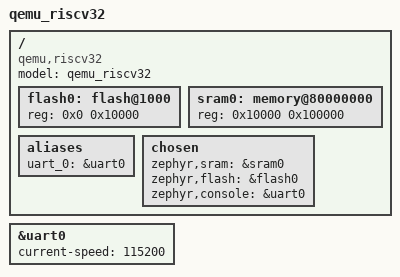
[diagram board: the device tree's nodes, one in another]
/dts-v1/;

#include <riscv32-qemu.dtsi>

/ {
	model = "qemu_riscv32";
	compatible = "qemu,riscv32";

        flash0: flash@1000 {
		/delete-property/ reg;
                reg = <0x0 0x10000>;
        };

         sram0: memory@80000000 {
		/delete-property/ reg;
                reg = <0x10000 0x100000>;
        };

	aliases {
		uart_0 = &uart0;
	};

	chosen {
		zephyr,sram = &sram0;
		zephyr,flash = &flash0;
		zephyr,console = &uart0;
	};
};

&uart0 {
	status = "ok";
	current-speed = <115200>;
};
